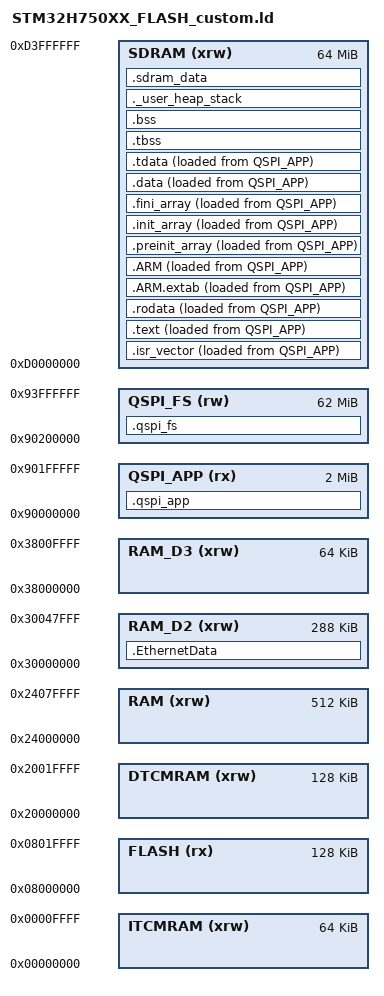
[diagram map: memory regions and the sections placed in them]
/*
******************************************************************************
**

**  File        : LinkerScript.ld
**
**  Author		: STM32CubeMX
**
**  Abstract    : Linker script for STM32H750XBHx series
**                128Kbytes FLASH and 1056Kbytes RAM
**
**                Set heap size, stack size and stack location according
**                to application requirements.
**
**                Set memory bank area and size if external memory is used.
**
**  Target      : STMicroelectronics STM32
**
**  Distribution: The file is distributed “as is,” without any warranty
**                of any kind.
**
*****************************************************************************
** @attention
**
** <h2><center>&copy; COPYRIGHT(c) 2025 STMicroelectronics</center></h2>
**
** Redistribution and use in source and binary forms, with or without modification,
** are permitted provided that the following conditions are met:
**   1. Redistributions of source code must retain the above copyright notice,
**      this list of conditions and the following disclaimer.
**   2. Redistributions in binary form must reproduce the above copyright notice,
**      this list of conditions and the following disclaimer in the documentation
**      and/or other materials provided with the distribution.
**   3. Neither the name of STMicroelectronics nor the names of its contributors
**      may be used to endorse or promote products derived from this software
**      without specific prior written permission.
**
** THIS SOFTWARE IS PROVIDED BY THE COPYRIGHT HOLDERS AND CONTRIBUTORS "AS IS"
** AND ANY EXPRESS OR IMPLIED WARRANTIES, INCLUDING, BUT NOT LIMITED TO, THE
** IMPLIED WARRANTIES OF MERCHANTABILITY AND FITNESS FOR A PARTICULAR PURPOSE ARE
** DISCLAIMED. IN NO EVENT SHALL THE COPYRIGHT HOLDER OR CONTRIBUTORS BE LIABLE
** FOR ANY DIRECT, INDIRECT, INCIDENTAL, SPECIAL, EXEMPLARY, OR CONSEQUENTIAL
** DAMAGES (INCLUDING, BUT NOT LIMITED TO, PROCUREMENT OF SUBSTITUTE GOODS OR
** SERVICES; LOSS OF USE, DATA, OR PROFITS; OR BUSINESS INTERRUPTION) HOWEVER
** CAUSED AND ON ANY THEORY OF LIABILITY, WHETHER IN CONTRACT, STRICT LIABILITY,
** OR TORT (INCLUDING NEGLIGENCE OR OTHERWISE) ARISING IN ANY WAY OUT OF THE USE
** OF THIS SOFTWARE, EVEN IF ADVISED OF THE POSSIBILITY OF SUCH DAMAGE.
**
*****************************************************************************
*/

/* Entry Point */
ENTRY(Reset_Handler)

/* Specify the memory areas */
MEMORY
{
DTCMRAM (xrw)      : ORIGIN = 0x20000000, LENGTH = 128K
RAM (xrw)      : ORIGIN = 0x24000000, LENGTH = 512K
RAM_D2 (xrw)      : ORIGIN = 0x30000000, LENGTH = 288K
RAM_D3 (xrw)      : ORIGIN = 0x38000000, LENGTH = 64K
ITCMRAM (xrw)      : ORIGIN = 0x00000000, LENGTH = 64K
SDRAM (xrw)      : ORIGIN = 0xD0000000, LENGTH = 64M
FLASH (rx)      : ORIGIN = 0x8000000, LENGTH = 128K
QSPI_APP (rx)   : ORIGIN = 0x90000000, LENGTH = 2M
QSPI_FS (rw)    : ORIGIN = 0x90200000, LENGTH = 62M
}

/* Highest address of the user mode stack */
_estack = ORIGIN(SDRAM) + LENGTH(SDRAM);    /* end of SDRAM - stack grows down */
/* Generate a link error if heap and stack don't fit into RAM */
_Min_Heap_Size = 0x2000000;      /* 32MB heap for Doom  */
_Min_Stack_Size = 0x20000; /* 128KB stack */

/* Define output sections */
SECTIONS
{
  /* The startup code - stored in QSPI, runs from SDRAM */
  .isr_vector :
  {
    . = ALIGN(4);
    KEEP(*(.isr_vector)) /* Startup code */
    . = ALIGN(4);
  } >SDRAM AT>QSPI_APP

  /* The program code - stored in QSPI, runs from SDRAM */
  .text : ALIGN(64)
  {
    . = ALIGN(64);
    *(.text)           /* .text sections (code) */
    *(.text*)          /* .text* sections (code) */
    *(.glue_7)         /* glue arm to thumb code */
    *(.glue_7t)        /* glue thumb to arm code */
    *(.eh_frame)

    KEEP (*(.init))
    KEEP (*(.fini))

    . = ALIGN(4);
    _etext = .;        /* define a global symbols at end of code */
  } >SDRAM AT>QSPI_APP

  /* Constant data - stored in QSPI, runs from SDRAM */
  .rodata :
  {
    . = ALIGN(4);
    *(.rodata)         /* .rodata sections (constants, strings, etc.) */
    *(.rodata*)        /* .rodata* sections (constants, strings, etc.) */
    . = ALIGN(4);
  } >SDRAM AT>QSPI_APP

  .ARM.extab (READONLY) : /* The "READONLY" keyword is only supported in GCC11 and later, remove it if using GCC10 or earlier. */
  {
    . = ALIGN(4);
    *(.ARM.extab* .gnu.linkonce.armextab.*)
    . = ALIGN(4);
  } >SDRAM AT>QSPI_APP

  .ARM (READONLY) : /* The "READONLY" keyword is only supported in GCC11 and later, remove it if using GCC10 or earlier. */
  {
    . = ALIGN(4);
    __exidx_start = .;
    *(.ARM.exidx*)
    __exidx_end = .;
    . = ALIGN(4);
  } >SDRAM AT>QSPI_APP

  .preinit_array (READONLY) : /* The "READONLY" keyword is only supported in GCC11 and later, remove it if using GCC10 or earlier. */
  {
    . = ALIGN(4);
    PROVIDE_HIDDEN (__preinit_array_start = .);
    KEEP (*(.preinit_array*))
    PROVIDE_HIDDEN (__preinit_array_end = .);
    . = ALIGN(4);
  } >SDRAM AT>QSPI_APP

  .init_array (READONLY) : /* The "READONLY" keyword is only supported in GCC11 and later, remove it if using GCC10 or earlier. */
  {
    . = ALIGN(4);
    PROVIDE_HIDDEN (__init_array_start = .);
    KEEP (*(SORT(.init_array.*)))
    KEEP (*(.init_array*))
    PROVIDE_HIDDEN (__init_array_end = .);
    . = ALIGN(4);
  } >SDRAM AT>QSPI_APP

  .fini_array (READONLY) : /* The "READONLY" keyword is only supported in GCC11 and later, remove it if using GCC10 or earlier. */
  {
    . = ALIGN(4);
    PROVIDE_HIDDEN (__fini_array_start = .);
    KEEP (*(SORT(.fini_array.*)))
    KEEP (*(.fini_array*))
    PROVIDE_HIDDEN (__fini_array_end = .);
    . = ALIGN(4);
  } >SDRAM AT>QSPI_APP

  /* used by the startup to initialize data */
  _sidata = LOADADDR(.data);

  /* Initialized data sections - stored in QSPI, runs from SDRAM */
  .data :
  {
    . = ALIGN(4);
    _sdata = .;        /* create a global symbol at data start */
    *(.data)           /* .data sections */
    *(.data*)          /* .data* sections */
    *(.RamFunc)        /* .RamFunc sections */
    *(.RamFunc*)       /* .RamFunc* sections */

    . = ALIGN(4);
  } >SDRAM AT>QSPI_APP

 /* Initialized TLS data section */
  .tdata : ALIGN(4)
  {
    *(.tdata .tdata.* .gnu.linkonce.td.*)
    . = ALIGN(4);
    _edata = .;        /* define a global symbol at data end */
    PROVIDE(__data_end = .);
    PROVIDE(__tdata_end = .);
  } >SDRAM AT>QSPI_APP

  PROVIDE( __tdata_start = ADDR(.tdata) );
  PROVIDE( __tdata_size = __tdata_end - __tdata_start );

  PROVIDE( __data_start = ADDR(.data) );
  PROVIDE( __data_size = __data_end - __data_start );

  PROVIDE( __tdata_source = LOADADDR(.tdata) );
  PROVIDE( __tdata_source_end = LOADADDR(.tdata) + SIZEOF(.tdata) );
  PROVIDE( __tdata_source_size = __tdata_source_end - __tdata_source );

  PROVIDE( __data_source = LOADADDR(.data) );
  PROVIDE( __data_source_end = __tdata_source_end );
  PROVIDE( __data_source_size = __data_source_end - __data_source );
  /* Uninitialized data section */
  .tbss (NOLOAD) : ALIGN(4)
  {
     /* This is used by the startup in order to initialize the .bss secion */
    _sbss = .;         /* define a global symbol at bss start */
    __bss_start__ = _sbss;
    *(.tbss .tbss.*)
    . = ALIGN(4);
    PROVIDE( __tbss_end = . );
  } >SDRAM

  PROVIDE( __tbss_start = ADDR(.tbss) );
  PROVIDE( __tbss_size = __tbss_end - __tbss_start );
  PROVIDE( __tbss_offset = ADDR(.tbss) - ADDR(.tdata) );

  PROVIDE( __tls_base = __tdata_start );
  PROVIDE( __tls_end = __tbss_end );
  PROVIDE( __tls_size = __tls_end - __tls_base );
  PROVIDE( __tls_align = MAX(ALIGNOF(.tdata), ALIGNOF(.tbss)) );
  PROVIDE( __tls_size_align = (__tls_size + __tls_align - 1) & ~(__tls_align - 1) );
  PROVIDE( __arm32_tls_tcb_offset = MAX(8, __tls_align) );
  PROVIDE( __arm64_tls_tcb_offset = MAX(16, __tls_align) );

  .bss (NOLOAD) : ALIGN(4)
  {
    *(.bss)
    *(.bss*)
    *(COMMON)

      . = ALIGN(4);
    _ebss = .;         /* define a global symbol at bss end */
    __bss_end__ = _ebss;
      PROVIDE( __bss_end = .);
  } >SDRAM
  PROVIDE( __non_tls_bss_start = ADDR(.bss) );

  PROVIDE( __bss_start = __tbss_start );
  PROVIDE( __bss_size = __bss_end - __bss_start );

  /* User_heap_stack section, used to check that there is enough SDRAM left */
  ._user_heap_stack (NOLOAD) :
  {
    . = ALIGN(8);
    PROVIDE ( end = . );
    PROVIDE ( _end = . );
    . = . + _Min_Heap_Size;
    . = . + _Min_Stack_Size;
    . = ALIGN(8);
  } >SDRAM

  /* SDRAM section for framebuffers and other large data structures */
  .sdram_data (NOLOAD) :
  {
    . = ALIGN(4);
    *(.sdram_data)
    *(.sdram_data*)
    . = ALIGN(4);
  } >SDRAM

  /* Ethernet DMA descriptors and buffers - must be in RAM_D2 for DMA access */
  .EthernetData (NOLOAD) :
  {
    . = ALIGN(32);
    *(.RxDecripSection)
    . = ALIGN(32);
    *(.TxDecripSection)
    . = ALIGN(32);
    *(.Rx_PoolSection)
    . = ALIGN(32);

    . = 0x6000; /* Offset from D2 start */
    __lwip_heap_start = .;
    . = . + 32K;
    __lwip_heap_end = .;
    . = ALIGN(32);

  } >RAM_D2

  /* QSPI File System section - embedded FAT filesystem image */
  .qspi_fs :
  {
    . = ALIGN(4);
    KEEP(*(.qspi_fs_data))
    . = ALIGN(4);
  } >QSPI_FS

  /* Optional: QSPI executable code section (XIP - Execute In Place) */
  .qspi_app :
  {
    . = ALIGN(4);
    KEEP(*(.qspi_app))
    *(.qspi_code)
    *(.qspi_code*)
    . = ALIGN(4);
  } >QSPI_APP

  PROVIDE( __qspi_fs_start = ORIGIN(QSPI_FS) );
  PROVIDE( __qspi_fs_end = ORIGIN(QSPI_FS) + LENGTH(QSPI_FS) );
  PROVIDE( __qspi_fs_size = LENGTH(QSPI_FS) );

  PROVIDE( __qspi_fs_start = ORIGIN(QSPI_FS) );
  PROVIDE( __qspi_fs_end = ORIGIN(QSPI_FS) + LENGTH(QSPI_FS) );
  PROVIDE( __qspi_fs_size = LENGTH(QSPI_FS) );

  /* Remove information from the standard libraries */
  /DISCARD/ :
  {
    libc.a:* ( * )
    libm.a:* ( * )
    libgcc.a:* ( * )
  }

}
